# InterruptGeneratorIfc: IP-XACT component
VLNV eccelerators.com:interface:InterruptGeneratorIfc:0.0.1

## Address spaces and blocks
InterruptGeneratorBlk.ControlReg: base 0, range 4, width 8
InterruptGeneratorBlk.StatusReg: base 4, range 4, width 8
InterruptGeneratorBlk.ChargedCountReg0: base 8, range 4, width 8
InterruptGeneratorBlk.ChargedCountReg1: base 12, range 4, width 8
InterruptGeneratorBlk.ChargedCountReg2: base 16, range 4, width 8
InterruptGeneratorBlk.ChargedCountReg3: base 20, range 4, width 8
InterruptGeneratorBlk.ActualCountReg0: base 24, range 4, width 8
InterruptGeneratorBlk.ActualCountReg1: base 28, range 4, width 8
InterruptGeneratorBlk.ActualCountReg2: base 32, range 4, width 8
InterruptGeneratorBlk.ActualCountReg3: base 36, range 4, width 8
InterruptGeneratorBlk.FailureCountReg0: base 40, range 4, width 8
InterruptGeneratorBlk.FailureCountReg1: base 44, range 4, width 8
InterruptGeneratorBlk.FailureCountReg2: base 48, range 4, width 8
InterruptGeneratorBlk.FailureCountReg3: base 52, range 4, width 8
InterruptGeneratorBlk.IntervalReg0: base 56, range 4, width 8
InterruptGeneratorBlk.IntervalReg1: base 60, range 4, width 8
InterruptGeneratorBlk.IntervalReg2: base 64, range 4, width 8
InterruptGeneratorBlk.IntervalReg3: base 68, range 4, width 8
InterruptGeneratorBlk.ReferenceCountReg0: base 72, range 4, width 8
InterruptGeneratorBlk.ReferenceCountReg1: base 76, range 4, width 8
InterruptGeneratorBlk.ReferenceCountReg2: base 80, range 4, width 8
InterruptGeneratorBlk.ReferenceCountReg3: base 84, range 4, width 8

## Registers
Registers are 32-bit, read-write, no defined reset value unless marked. A register's access mark holds for its fields unless they carry their own. Offsets are from the block's base; lines under a group give offsets from that group; [hi:lo] are bit positions; {n}, {i} and the like mark numbered series; 'fields as' and 'values as' point back to an identical list; <NAME> marks a mode.

## InterruptGeneratorBlk.ControlReg
Base 0x00000000
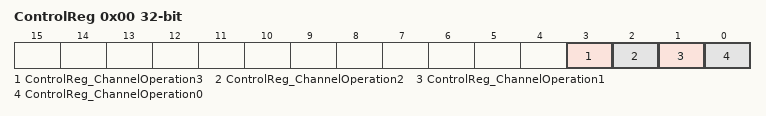
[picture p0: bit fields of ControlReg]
0x00 ControlReg — Control Register
  [3] ControlReg_ChannelOperation3
    0=ControlReg_ChannelOperation3_Disabled (An Interrupt is not pending.); 8=ControlReg_ChannelOperation3_Enabled (An Interrupt is pending.)
  [2] ControlReg_ChannelOperation2
    0=ControlReg_ChannelOperation2_Disabled (An Interrupt is not pending.); 4=ControlReg_ChannelOperation2_Enabled (An Interrupt is pending.)
  [1] ControlReg_ChannelOperation1
    0=ControlReg_ChannelOperation1_Disabled (An Interrupt is not pending.); 2=ControlReg_ChannelOperation1_Enabled (An Interrupt is pending.)
  [0] ControlReg_ChannelOperation0
    0=ControlReg_ChannelOperation0_Disabled (An Interrupt is not pending.); 1=ControlReg_ChannelOperation0_Enabled (An Interrupt is pending.)

## InterruptGeneratorBlk.StatusReg
Base 0x00000004
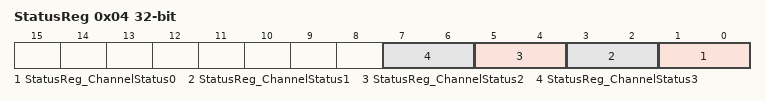
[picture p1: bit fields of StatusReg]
0x04 StatusReg ro — Status Register
  [2n+1:2n] StatusReg_ChannelStatus{n} (n=0..3)
    0=StatusReg_ChannelStatus{n}_Idle; 1=StatusReg_ChannelStatus{n}_Operating; 2=StatusReg_ChannelStatus{n}_Ended

## InterruptGeneratorBlk.ChargedCountReg0
Base 0x00000008
0x08 ChargedCountReg0 — Charged Count Register
  [31:0] ChargedCountReg0_Count — Number of interrupts to be generated and expected to be handled by SW.

## InterruptGeneratorBlk.ChargedCountReg1
Base 0x0000000C
0x0C ChargedCountReg1 — Charged Count Register
  [31:0] ChargedCountReg1_Count — Number of interrupts to be generated and expected to be handled by SW.

## InterruptGeneratorBlk.ChargedCountReg2
Base 0x00000010
0x10 ChargedCountReg2 — Charged Count Register
  [31:0] ChargedCountReg2_Count — Number of interrupts to be generated and expected to be handled by SW.

## InterruptGeneratorBlk.ChargedCountReg3
Base 0x00000014
0x14 ChargedCountReg3 — Charged Count Register
  [31:0] ChargedCountReg3_Count — Number of interrupts to be generated and expected to be handled by SW.

## InterruptGeneratorBlk.ActualCountReg0
Base 0x00000018
0x18 ActualCountReg0 ro — Actual Count Register
  [31:0] ActualCountReg0_Count — Actual count of interrupts already generated.

## InterruptGeneratorBlk.ActualCountReg1
Base 0x0000001C
0x1C ActualCountReg1 ro — Actual Count Register
  [31:0] ActualCountReg1_Count — Actual count of interrupts already generated.

## InterruptGeneratorBlk.ActualCountReg2
Base 0x00000020
0x20 ActualCountReg2 ro — Actual Count Register
  [31:0] ActualCountReg2_Count — Actual count of interrupts already generated.

## InterruptGeneratorBlk.ActualCountReg3
Base 0x00000024
0x24 ActualCountReg3 ro — Actual Count Register
  [31:0] ActualCountReg3_Count — Actual count of interrupts already generated.

## InterruptGeneratorBlk.FailureCountReg0
Base 0x00000028
0x28 FailureCountReg0 ro — Failure Count Register
  [31:0] FailureCountReg0_Count — Failure count of missed interrupts.

## InterruptGeneratorBlk.FailureCountReg1
Base 0x0000002C
0x2C FailureCountReg1 ro — Failure Count Register
  [31:0] FailureCountReg1_Count — Failure count of missed interrupts.

## InterruptGeneratorBlk.FailureCountReg2
Base 0x00000030
0x30 FailureCountReg2 ro — Failure Count Register
  [31:0] FailureCountReg2_Count — Failure count of missed interrupts.

## InterruptGeneratorBlk.FailureCountReg3
Base 0x00000034
0x34 FailureCountReg3 ro — Failure Count Register
  [31:0] FailureCountReg3_Count — Failure count of missed interrupts.

## InterruptGeneratorBlk.IntervalReg0
Base 0x00000038
0x38 IntervalReg0 — Interval Register
  [31:0] IntervalReg0_Interval — Interval of generated interrupt in nanaoseconds.

## InterruptGeneratorBlk.IntervalReg1
Base 0x0000003C
0x3C IntervalReg1 — Interval Register
  [31:0] IntervalReg1_Interval — Interval of generated interrupt in nanaoseconds.

## InterruptGeneratorBlk.IntervalReg2
Base 0x00000040
0x40 IntervalReg2 — Interval Register
  [31:0] IntervalReg2_Interval — Interval of generated interrupt in nanaoseconds.

## InterruptGeneratorBlk.IntervalReg3
Base 0x00000044
0x44 IntervalReg3 — Interval Register
  [31:0] IntervalReg3_Interval — Interval of generated interrupt in nanaoseconds.

## InterruptGeneratorBlk.ReferenceCountReg0
Base 0x00000048
0x48 ReferenceCountReg0 — Reference Count Register
  [31:0] ReferenceCountReg0_Count — Reference count written by SW to acknowledge a processed interrupt.

## InterruptGeneratorBlk.ReferenceCountReg1
Base 0x0000004C
0x4C ReferenceCountReg1 — Reference Count Register
  [31:0] ReferenceCountReg1_Count — Reference count written by SW to acknowledge a processed interrupt.

## InterruptGeneratorBlk.ReferenceCountReg2
Base 0x00000050
0x50 ReferenceCountReg2 — Reference Count Register
  [31:0] ReferenceCountReg2_Count — Reference count written by SW to acknowledge a processed interrupt.

## InterruptGeneratorBlk.ReferenceCountReg3
Base 0x00000054
0x54 ReferenceCountReg3 — Reference Count Register
  [31:0] ReferenceCountReg3_Count — Reference count written by SW to acknowledge a processed interrupt.
